# ICONT1_CFG_ICONT register map
Vendor: Texas Instruments
Peripheral module from a debugger description file (folder DRA75x_DRA74x).
Registers are 32-bit, read-only, reset values left out (the file's numbers can be read two ways) unless marked. A register's access mark holds for its fields unless they carry their own. Offsets are as the file gives them; lines under a group give offsets from that group; [hi:lo] are bit positions; {n}, {i} and the like mark numbered series; 'fields as' and 'values as' point back to an identical list; <NAME> marks a mode.

## ICONT1_CFG_ICONT
0x00 ICONT_REVISION — ICONT Revision Identifier (X.Y.R) Used by software to track features, bugs, and compatibility
  [31:0] VERSION — Module Version
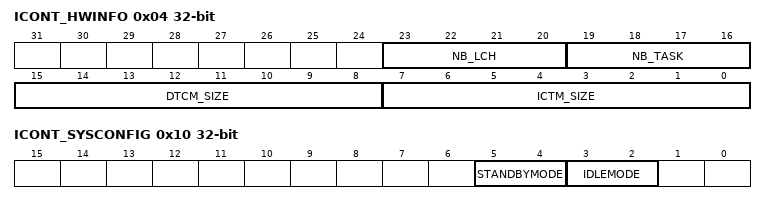
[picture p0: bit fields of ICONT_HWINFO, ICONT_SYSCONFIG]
0x04 ICONT_HWINFO — Information about the IP module's hardware configuration.
  [23:20] NB_LCH — Number of Data Mover Logical channel
  [19:16] NB_TASK — Number of SYNCBOX tasks
  [15:8] DTCM_SIZE — Size of DTCM (in kBytes)
  [7:0] ICTM_SIZE — Size of ITCM (in kBytes)
0x10 ICONT_SYSCONFIG access per field — Clock management configuration
  [5:4] STANDBYMODE rw — Configuration of the local initiator state management mode. By definition, initiator may generate read/write transaction as long as it is out of STANDBY state.
    0=Force-standby mode: local initiator is unconditionally placed in standby state. Backup mode, for debug only.; 1=No-standby mode: local initiator is unconditionally placed out of standby state. Backup mode, for debug only.; 2=IP_2 (Smart-standby mode: local initiator standby status depends on local conditions, that is, the module's functional requirement from the initiator. IP module shall not generate (initiator-related) wakeup events.)
  [3:2] IDLEMODE rw — Configuration of the local target state management mode. By definition, target can handle read/write transaction as long as it is out of IDLE state.
    0=IP_0 (Force-idle mode: local target's idle state follows (acknowledges) the system's idle requests unconditionally, that is, regardless of the IP module's internal requirements. Backup mode, for debug only.); 1=No-idle mode: local target never enters idle state. Backup mode, for debug only.; 2=IP_IP_(IRQ-_2 (Smart-idle mode: local target's idle state eventually follows (acknowledges) the system's idle requests, depending on the IP module's internal requirements. IP module shall not generate (IRQ- or DMA-request-related) wakeup events.)
